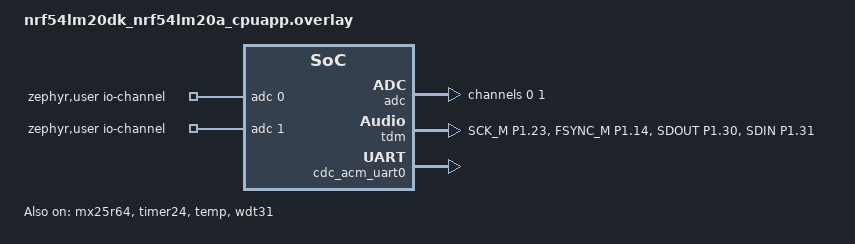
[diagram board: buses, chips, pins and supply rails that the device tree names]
/*
 * Copyright (c) 2025 Nordic Semiconductor ASA
 *
 * SPDX-License-Identifier: LicenseRef-Nordic-5-Clause
 */

/ {
	aliases {
		i2s-node0 = &tdm;
		test-counter = &timer24;
	};

	zephyr,user {
		io-channels = <&adc 0>, <&adc 1>;
	};
};

&pinctrl {
	tdm_default_alt: tdm_default_alt {
		group1 {
			psels = <NRF_PSEL(TDM_SCK_M, 1, 23)>,
				<NRF_PSEL(TDM_FSYNC_M, 1, 14)>,
				<NRF_PSEL(TDM_SDOUT, 1, 30)>,
				<NRF_PSEL(TDM_SDIN, 1, 31)>;
		};
	};
};

&adc {
	status = "okay";
	#address-cells = <1>;
	#size-cells = <0>;

	channel@0 {
		reg = <0>;
		zephyr,gain = "ADC_GAIN_1";
		zephyr,reference = "ADC_REF_INTERNAL";
		zephyr,acquisition-time = <ADC_ACQ_TIME(ADC_ACQ_TIME_MICROSECONDS, 10)>;
		zephyr,input-positive = <NRF_SAADC_AIN4>; /* P1.06 */
		zephyr,resolution = <10>;
	};

	channel@1 {
		reg = <1>;
		zephyr,gain = "ADC_GAIN_1_4";
		zephyr,reference = "ADC_REF_INTERNAL";
		zephyr,acquisition-time = <ADC_ACQ_TIME_DEFAULT>;
		zephyr,input-positive = <NRF_SAADC_AIN5>; /* P1.05 */
		zephyr,resolution = <12>;
	};
};

&mx25r64 {
	status = "okay";
};

&tdm {
	status = "okay";
	pinctrl-0 = <&tdm_default_alt>;
	pinctrl-names = "default";
};

&timer24 {
	status = "okay";
	prescaler = <4>;
};

temp_sensor: &temp {
	status = "okay";
};

&wdt31 {
	status = "okay";
};

&zephyr_udc0 {
	cdc_acm_uart0 {
		compatible = "zephyr,cdc-acm-uart";
	};
};
